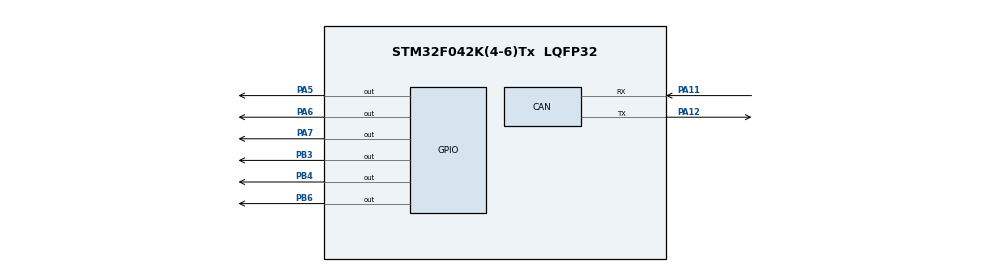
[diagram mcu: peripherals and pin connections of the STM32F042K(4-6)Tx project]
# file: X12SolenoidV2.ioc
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CAN.CalculateTimeQuantum=2000.0
Mcu.Family=STM32F0
Mcu.Name=STM32F042K(4-6)Tx
Mcu.Package=LQFP32
PA11.Mode=Master
PA11.Signal=CAN_RX
PA12.Mode=Master
PA12.Signal=CAN_TX
PA5.Signal=GPIO_Output
PA6.Signal=GPIO_Output
PA7.Signal=GPIO_Output
PB3.Signal=GPIO_Output
PB4.Signal=GPIO_Output
PB6.Signal=GPIO_Output
ProjectManager.HeapSize=0x200
ProjectManager.StackSize=0x400
ProjectManager.TargetToolchain=STM32CubeIDE
board=custom

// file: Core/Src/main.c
/* USER CODE BEGIN Header */
/**
  ******************************************************************************
  * @file           : main.c
  * @brief          : Main program body
  ******************************************************************************
  * @attention
  *
  * <h2><center>&copy; Copyright (c) 2020 STMicroelectronics.
  * All rights reserved.</center></h2>
  *
  * This software component is licensed by ST under BSD 3-Clause license,
  * the "License"; You may not use this file except in compliance with the
  * License. You may obtain a copy of the License at:
  *                        opensource.org/licenses/BSD-3-Clause
  *
  ******************************************************************************
  */
/* USER CODE END Header */
#include "main.h"
#include "solenoid.h"

/* USER CODE BEGIN PD */
#define NUM_SOLENOIDS 6
/* USER CODE END PD */

CAN_HandleTypeDef hcan;

//  Establish Pins used for solenoids
int solenoidIndices[NUM_SOLENOIDS] = {0, 1, 2, 3, 4, 5};
GPIO_TypeDef* gpioPorts[NUM_SOLENOIDS] = {GPIOA, GPIOA, GPIOA, GPIOB, GPIOB, GPIOB};
uint16_t gpioPins[NUM_SOLENOIDS] = {GPIO_PIN_7, GPIO_PIN_6, GPIO_PIN_5, GPIO_PIN_6, GPIO_PIN_4, GPIO_PIN_3};

void SystemClock_Config(void);
static void MX_GPIO_Init(void);
static void MX_CAN_Init(void);

int main(void)
{

  /* MCU Configuration--------------------------------------------------------*/

  /* Reset of all peripherals, Initializes the Flash interface and the Systick. */
  HAL_Init();

  /* Configure the system clock */
  SystemClock_Config();

  /* Initialize all configured peripherals */
  MX_GPIO_Init();
  MX_CAN_Init();

  /* Infinite loop */
  while (1)
  {

  }
}

void SystemClock_Config(void)
{
  RCC_OscInitTypeDef RCC_OscInitStruct = {0};
  RCC_ClkInitTypeDef RCC_ClkInitStruct = {0};

  /** Initializes the RCC Oscillators according to the specified parameters
  * in the RCC_OscInitTypeDef structure.
  */
  RCC_OscInitStruct.OscillatorType = RCC_OSCILLATORTYPE_HSI;
  RCC_OscInitStruct.HSIState = RCC_HSI_ON;
  RCC_OscInitStruct.HSICalibrationValue = RCC_HSICALIBRATION_DEFAULT;
  RCC_OscInitStruct.PLL.PLLState = RCC_PLL_NONE;
  if (HAL_RCC_OscConfig(&RCC_OscInitStruct) != HAL_OK)
  {
    Error_Handler();
  }
  /** Initializes the CPU, AHB and APB buses clocks
  */
  RCC_ClkInitStruct.ClockType = RCC_CLOCKTYPE_HCLK|RCC_CLOCKTYPE_SYSCLK
                              |RCC_CLOCKTYPE_PCLK1;
  RCC_ClkInitStruct.SYSCLKSource = RCC_SYSCLKSOURCE_HSI;
  RCC_ClkInitStruct.AHBCLKDivider = RCC_SYSCLK_DIV1;
  RCC_ClkInitStruct.APB1CLKDivider = RCC_HCLK_DIV1;

  if (HAL_RCC_ClockConfig(&RCC_ClkInitStruct, FLASH_LATENCY_0) != HAL_OK)
  {
    Error_Handler();
  }
}

#define SOLENOID_BOARD_CAN_STANDARD_ID 0x204  //  11 bits
#define SOLENOID_BOARD_CAN_EXTENDED_ID 0x00000  //  18 bits
#define SOLENOID_BOARD_CAN_IDE 0
#define SOLENOID_BOARD_CAN_RTR 0

static void MX_CAN_Init(void)
{
	//  Note:
	// 	HAL_CAN_MspInit() defined in Core/Src/stm32f0xx_hal_msp.c
	//  Enables GPIO Pins PA11 and PA12 for CAN RX and TX, respectively
	// 	Enables CAN Peripheral CLK
	//  Enables CAN Interrupt through NVIC

	//  Generated Code
	hcan.Instance = CAN;
	hcan.Init.Prescaler = 4;
	hcan.Init.Mode = CAN_MODE_NORMAL;
	hcan.Init.SyncJumpWidth = CAN_SJW_4TQ;
	hcan.Init.TimeSeg1 = CAN_BS1_11TQ;
	hcan.Init.TimeSeg2 = CAN_BS2_4TQ;
	hcan.Init.TimeTriggeredMode = DISABLE;
	hcan.Init.AutoBusOff = DISABLE;
	hcan.Init.AutoWakeUp = ENABLE;
	hcan.Init.AutoRetransmission = DISABLE;
	hcan.Init.ReceiveFifoLocked = DISABLE;
	hcan.Init.TransmitFifoPriority = DISABLE;
	if (HAL_CAN_Init(&hcan) != HAL_OK)
	{
		Error_Handler();
	}

	//  Configure CAN RX Filter
	CAN_FilterTypeDef solenoidBoardFilter;
	//  Filter Bank #0 assigned to FIFO #0 (two total RX FIFOs)
	solenoidBoardFilter.FilterBank = 0;
	solenoidBoardFilter.FilterFIFOAssignment = CAN_FILTER_FIFO0;

	//  Configure Filter Bank #0 as 32-bit Scale in Identifier Mask Mode
	solenoidBoardFilter.FilterMode = CAN_FILTERMODE_IDMASK;
	solenoidBoardFilter.FilterScale = CAN_FILTERSCALE_32BIT;

	//  Set CAN Filter ID High
	//  [11 bit STDID][18 bit Extended ID][1 bit IDE][1 bit RTR][1'b0]
	//  FilterIdHigh is 16 MSbits
	//  FilterIdLow is 16 LSbits
	solenoidBoardFilter.FilterIdHigh = (SOLENOID_BOARD_CAN_STANDARD_ID << 5);
	solenoidBoardFilter.FilterIdHigh |= ((SOLENOID_BOARD_CAN_EXTENDED_ID & (0x1F << 13)) >> 13);
	solenoidBoardFilter.FilterIdLow = (SOLENOID_BOARD_CAN_EXTENDED_ID & 0x1FFF) << 3;
	solenoidBoardFilter.FilterIdLow |= (SOLENOID_BOARD_CAN_IDE << 2);
	solenoidBoardFilter.FilterIdLow |= (SOLENOID_BOARD_CAN_RTR << 1);

	//  Set CAN Filter Mask
	//  Bits directly correspond to bits in Filter
	//  Each bit HIGH in the Mask has to Match for Message
	//  of specific CAN ID to be filter through into CAN RX FIFO
	solenoidBoardFilter.FilterMaskIdHigh = (0x7FF << 5);  //  Only Match STDID
	solenoidBoardFilter.FilterMaskIdLow = (0x03 << 1);  //  Only Match IDE and RTR bits

	//  Enable Solenoid Board Filter
	solenoidBoardFilter.FilterActivation = CAN_FILTER_ENABLE;

	//  Configure Filter
	if (HAL_CAN_ConfigFilter(&hcan, &solenoidBoardFilter) != HAL_OK)
	{
		Error_Handler();
	}

	//  Enable CAN FIFO RX Pending Interrupt
	if (HAL_CAN_ActivateNotification(&hcan, CAN_IT_RX_FIFO0_MSG_PENDING) != HAL_OK)
	{
		Error_Handler();
	}

	HAL_CAN_RegisterCallback(&hcan, HAL_CAN_RX_FIFO0_MSG_PENDING_CB_ID, CAN_ReceiveMessageCallback);
}

void CAN_ReceiveMessageCallback(CAN_HandleTypeDef *hcan)
{
	CAN_RxHeaderTypeDef canPacketHeader;
	uint8_t canPacketData[8];

	if (HAL_CAN_GetRxMessage(hcan, CAN_RX_FIFO0, &canPacketHeader, canPacketData) != HAL_OK)
	{
		Error_Handler();
	}

	uint8_t solenoidData = canPacketData[7];
	for (int solenoidIndex = 0; solenoidIndex < NUM_SOLENOIDS; solenoidIndex++)
	{
		//  Enable Solenoid
		if ((solenoidData & (1 << solenoidIndex)) != 0)
		{
			enableSolenoid(solenoidIndex);
		}
		//  Disable Solenoid
		else
		{
			disableSolenoid(solenoidIndex);
		}
	}
}

static void MX_GPIO_Init(void)
{
  GPIO_InitTypeDef GPIO_InitStruct = {0};

  /* GPIO Ports Clock Enable */
  __HAL_RCC_GPIOA_CLK_ENABLE();
  __HAL_RCC_GPIOB_CLK_ENABLE();

  //  Configure GPIO for LED
  HAL_GPIO_WritePin(GPIOA, GPIO_PIN_15, GPIO_PIN_RESET);
  GPIO_InitStruct.Pin = GPIO_PIN_15;
  GPIO_InitStruct.Mode = GPIO_MODE_OUTPUT_PP;
  GPIO_InitStruct.Pull = GPIO_NOPULL;
  GPIO_InitStruct.Speed = GPIO_SPEED_FREQ_LOW;
  HAL_GPIO_Init(GPIOA, &GPIO_InitStruct);

  SolenoidInit();
}

SolenoidErrorCode SolenoidInit()
{
	SolenoidErrorCode errorCode;

	//  Set configuration settings for solenoid GPIO Pins
	GPIO_InitTypeDef gpioInit;
	gpioInit.Mode = GPIO_MODE_OUTPUT_PP;
	gpioInit.Pull = GPIO_NOPULL;
	gpioInit.Speed = GPIO_SPEED_FREQ_LOW;

	//  Verify and configure number of solenoids
	errorCode = verifyNumberOfSolenoids(NUM_SOLENOIDS);
	if (errorCode != SOLENOID_SUCCESS)
	{
		return errorCode;
	}
	configureNumberOfSolenoids(NUM_SOLENOIDS);

	//  Verify solenoids indices
	for (int i = 0; i < NUM_SOLENOIDS; i++)
	{
		errorCode = verifySolenoidIndex(solenoidIndices[i]);
		if (errorCode != SOLENOID_SUCCESS)
		{
			return errorCode;
		}
	}

	addSolenoids(NUM_SOLENOIDS, solenoidIndices, gpioPorts, gpioPins);
	configureSolenoids(&gpioInit);
	disableSolenoids();

	return SOLENOID_SUCCESS;
}

void Error_Handler(void)
{
}

/************************ (C) COPYRIGHT STMicroelectronics *****END OF FILE****/
